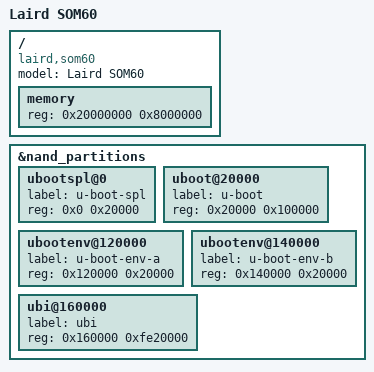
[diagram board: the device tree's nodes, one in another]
// SPDX-License-Identifier: GPL-2.0
/*
 * at91-som60.dtsi - Device Tree file for the SOM60 module
 *
 *  Copyright (C) 2018 Laird,
 *		  2018 Ben Whitten <ben.whitten@lairdconnect.com>
 *		  2018 Boris Krasnovskiy <boris.krasnovskiy@lairdconnect.com>
 *
 */
#include "at91-som60_common.dtsi"

/ {
	model = "Laird SOM60";
	compatible = "laird,som60", "atmel,sama5d36", "atmel,sama5d3", "atmel,sama5";

	memory {
		reg = <0x20000000 0x8000000>;
	};
};

&nand_partitions {
	ubootspl@0 {
		label = "u-boot-spl";
		reg = <0x0 0x20000>;
	};

	uboot@20000 {
		label = "u-boot";
		reg = <0x20000 0x100000>;
	};

	ubootenv@120000 {
		label = "u-boot-env-a";
		reg = <0x120000 0x20000>;
	};

	ubootenv@140000 {
		label = "u-boot-env-b";
		reg = <0x140000 0x20000>;
	};

	/* Leave last 4 blocks for bbt if nand-on-flash-bbt is defined */
	ubi@160000 {
		label = "ubi";
		reg = <0x160000 0xfe20000>;
	};
};
